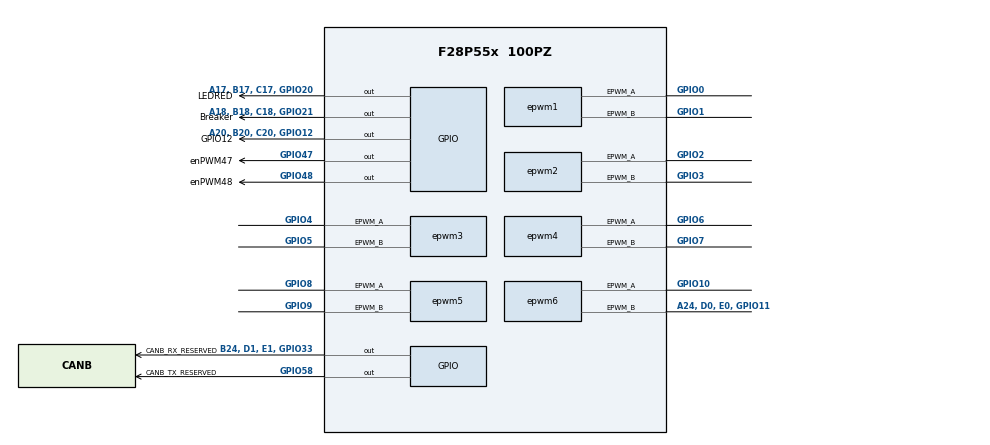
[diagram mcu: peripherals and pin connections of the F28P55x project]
/**
 * @cliArgs --device "F28P55x" --part "F28P55x_100PZ" --package "100PZ" --context "system" --product "C2000WARE@26.01.00.00"
 * @versions {"tool":"1.27.1+4634"}
 */

/**
 * Import the modules used in this configuration.
 */
const adc       = scripting.addModule("/driverlib/adc.js", {}, false);
const adc1      = adc.addInstance();
const adc2      = adc.addInstance();
const adc3      = adc.addInstance();
const adc4      = adc.addInstance();
const adc5      = adc.addInstance();
const analog    = scripting.addModule("/driverlib/analog.js", {}, false);
const analog1   = analog.addInstance();
const asysctl   = scripting.addModule("/driverlib/asysctl.js");
const cputimer  = scripting.addModule("/driverlib/cputimer.js", {}, false);
const cputimer1 = cputimer.addInstance();
const epwm      = scripting.addModule("/driverlib/epwm.js", {}, false);
const epwm1     = epwm.addInstance();
const epwm2     = epwm.addInstance();
const epwm3     = epwm.addInstance();
const epwm4     = epwm.addInstance();
const epwm5     = epwm.addInstance();
const epwm6     = epwm.addInstance();
const gpio      = scripting.addModule("/driverlib/gpio.js", {}, false);
const gpio1     = gpio.addInstance();
const gpio2     = gpio.addInstance();
const gpio3     = gpio.addInstance();
const gpio4     = gpio.addInstance();
const gpio5     = gpio.addInstance();
const gpio6     = gpio.addInstance();
const gpio7     = gpio.addInstance();

/**
 * Write custom configuration values to the imported modules.
 */
adc1.$name               = "ADC_A";
adc1.adcClockPrescaler   = "ADC_CLK_DIV_2_0";
adc1.soc0Trigger         = "ADC_TRIGGER_EPWM1_SOCA";
adc1.soc0SampleWindow    = 30;
adc1.soc1Trigger         = "ADC_TRIGGER_EPWM1_SOCA";
adc1.soc1SampleWindow    = 30;
adc1.soc2Trigger         = "ADC_TRIGGER_EPWM1_SOCA";
adc1.soc2SampleWindow    = 30;
adc1.soc3Channel         = "ADC_CH_ADCIN12";
adc1.soc3Trigger         = "ADC_TRIGGER_EPWM1_SOCA";
adc1.soc3SampleWindow    = 30;
adc1.enableTDMA          = false;
adc1.enabledInts         = ["ADC_INT_NUMBER1"];
adc1.enableInterrupt1    = true;
adc1.interruptPulseMode  = "ADC_PULSE_END_OF_CONV";
adc1.enabledSOCs         = ["ADC_SOC_NUMBER0","ADC_SOC_NUMBER1","ADC_SOC_NUMBER10","ADC_SOC_NUMBER11","ADC_SOC_NUMBER12","ADC_SOC_NUMBER13","ADC_SOC_NUMBER14","ADC_SOC_NUMBER15","ADC_SOC_NUMBER2","ADC_SOC_NUMBER3","ADC_SOC_NUMBER4","ADC_SOC_NUMBER5","ADC_SOC_NUMBER6","ADC_SOC_NUMBER7","ADC_SOC_NUMBER8","ADC_SOC_NUMBER9"];
adc1.soc4SampleWindow    = 30;
adc1.soc4Trigger         = "ADC_TRIGGER_EPWM1_SOCA";
adc1.soc5SampleWindow    = 30;
adc1.soc5Trigger         = "ADC_TRIGGER_EPWM1_SOCA";
adc1.soc6SampleWindow    = 30;
adc1.soc6Trigger         = "ADC_TRIGGER_EPWM1_SOCA";
adc1.soc7SampleWindow    = 30;
adc1.soc7Channel         = "ADC_CH_ADCIN12";
adc1.soc7Trigger         = "ADC_TRIGGER_EPWM1_SOCA";
adc1.soc8Trigger         = "ADC_TRIGGER_EPWM1_SOCA";
adc1.soc8SampleWindow    = 30;
adc1.soc9Trigger         = "ADC_TRIGGER_EPWM1_SOCA";
adc1.soc9SampleWindow    = 30;
adc1.soc10Trigger        = "ADC_TRIGGER_EPWM1_SOCA";
adc1.soc10SampleWindow   = 30;
adc1.soc11Channel        = "ADC_CH_ADCIN12";
adc1.soc11Trigger        = "ADC_TRIGGER_EPWM1_SOCA";
adc1.soc11SampleWindow   = 30;
adc1.soc12Trigger        = "ADC_TRIGGER_EPWM1_SOCA";
adc1.soc12SampleWindow   = 30;
adc1.soc13Trigger        = "ADC_TRIGGER_EPWM1_SOCA";
adc1.soc13SampleWindow   = 30;
adc1.soc14Trigger        = "ADC_TRIGGER_EPWM1_SOCA";
adc1.soc14SampleWindow   = 30;
adc1.soc15Channel        = "ADC_CH_ADCIN12";
adc1.soc15Trigger        = "ADC_TRIGGER_EPWM1_SOCA";
adc1.soc15SampleWindow   = 30;
adc1.interrupt1SOCSource = "ADC_INT_TRIGGER_EOC15";
adc1.soc1Channel         = "ADC_CH_ADCIN2";
adc1.soc2Channel         = "ADC_CH_ADCIN5";
adc1.soc5Channel         = "ADC_CH_ADCIN2";
adc1.soc6Channel         = "ADC_CH_ADCIN5";
adc1.soc9Channel         = "ADC_CH_ADCIN2";
adc1.soc10Channel        = "ADC_CH_ADCIN5";
adc1.soc13Channel        = "ADC_CH_ADCIN2";
adc1.soc14Channel        = "ADC_CH_ADCIN5";

adc2.$name               = "ADC_B";
adc2.adcBase             = "ADCB_BASE";
adc2.adcClockPrescaler   = "ADC_CLK_DIV_2_0";
adc2.soc0Trigger         = "ADC_TRIGGER_EPWM1_SOCA";
adc2.soc0SampleWindow    = 30;
adc2.enableTDMA          = false;
adc2.soc1Channel         = "ADC_CH_ADCIN1";
adc2.soc1Trigger         = "ADC_TRIGGER_EPWM1_SOCA";
adc2.soc1SampleWindow    = 30;
adc2.soc2Channel         = "ADC_CH_ADCIN8";
adc2.soc2Trigger         = "ADC_TRIGGER_EPWM1_SOCA";
adc2.soc2SampleWindow    = 30;
adc2.soc3SampleWindow    = 30;
adc2.soc3Channel         = "ADC_CH_ADCIN10";
adc2.soc3Trigger         = "ADC_TRIGGER_EPWM1_SOCA";
adc2.interruptPulseMode  = "ADC_PULSE_END_OF_CONV";
adc2.enabledInts         = ["ADC_INT_NUMBER1"];
adc2.enableInterrupt1    = true;
adc2.enabledSOCs         = ["ADC_SOC_NUMBER0","ADC_SOC_NUMBER1","ADC_SOC_NUMBER10","ADC_SOC_NUMBER11","ADC_SOC_NUMBER12","ADC_SOC_NUMBER13","ADC_SOC_NUMBER14","ADC_SOC_NUMBER15","ADC_SOC_NUMBER2","ADC_SOC_NUMBER3","ADC_SOC_NUMBER4","ADC_SOC_NUMBER5","ADC_SOC_NUMBER6","ADC_SOC_NUMBER7","ADC_SOC_NUMBER8","ADC_SOC_NUMBER9"];
adc2.soc4copyUse         = true;
adc2.soc4copyFrom        = "SOC0";
adc2.soc4Trigger         = "ADC_TRIGGER_EPWM1_SOCA";
adc2.soc4SampleWindow    = 30;
adc2.soc5copyUse         = true;
adc2.soc5copyFrom        = "SOC1";
adc2.soc5Channel         = "ADC_CH_ADCIN1";
adc2.soc5Trigger         = "ADC_TRIGGER_EPWM1_SOCA";
adc2.soc5SampleWindow    = 30;
adc2.soc6copyUse         = true;
adc2.soc6copyFrom        = "SOC2";
adc2.soc6Channel         = "ADC_CH_ADCIN8";
adc2.soc6Trigger         = "ADC_TRIGGER_EPWM1_SOCA";
adc2.soc6SampleWindow    = 30;
adc2.soc7copyUse         = true;
adc2.soc7copyFrom        = "SOC3";
adc2.soc7Channel         = "ADC_CH_ADCIN10";
adc2.soc7Trigger         = "ADC_TRIGGER_EPWM1_SOCA";
adc2.soc7SampleWindow    = 30;
adc2.soc8copyUse         = true;
adc2.soc8copyFrom        = "SOC0";
adc2.soc8Trigger         = "ADC_TRIGGER_EPWM1_SOCA";
adc2.soc8SampleWindow    = 30;
adc2.soc9copyUse         = true;
adc2.soc9copyFrom        = "SOC1";
adc2.soc9Channel         = "ADC_CH_ADCIN1";
adc2.soc9Trigger         = "ADC_TRIGGER_EPWM1_SOCA";
adc2.soc9SampleWindow    = 30;
adc2.soc10copyUse        = true;
adc2.soc10copyFrom       = "SOC2";
adc2.soc10Channel        = "ADC_CH_ADCIN8";
adc2.soc10Trigger        = "ADC_TRIGGER_EPWM1_SOCA";
adc2.soc10SampleWindow   = 30;
adc2.soc11copyUse        = true;
adc2.soc11copyFrom       = "SOC3";
adc2.soc11Channel        = "ADC_CH_ADCIN10";
adc2.soc11Trigger        = "ADC_TRIGGER_EPWM1_SOCA";
adc2.soc11SampleWindow   = 30;
adc2.soc12copyUse        = true;
adc2.soc12copyFrom       = "SOC0";
adc2.soc12Trigger        = "ADC_TRIGGER_EPWM1_SOCA";
adc2.soc12SampleWindow   = 30;
adc2.soc13copyUse        = true;
adc2.soc13copyFrom       = "SOC1";
adc2.soc13Channel        = "ADC_CH_ADCIN1";
adc2.soc13Trigger        = "ADC_TRIGGER_EPWM1_SOCA";
adc2.soc13SampleWindow   = 30;
adc2.soc14copyUse        = true;
adc2.soc14copyFrom       = "SOC2";
adc2.soc14Channel        = "ADC_CH_ADCIN8";
adc2.soc14Trigger        = "ADC_TRIGGER_EPWM1_SOCA";
adc2.soc14SampleWindow   = 30;
adc2.soc15copyUse        = true;
adc2.soc15copyFrom       = "SOC3";
adc2.soc15Channel        = "ADC_CH_ADCIN10";
adc2.soc15Trigger        = "ADC_TRIGGER_EPWM1_SOCA";
adc2.soc15SampleWindow   = 30;
adc2.interrupt1SOCSource = "ADC_INT_TRIGGER_EOC15";

adc3.$name               = "ADC_C";
adc3.adcBase             = "ADCC_BASE";
adc3.adcClockPrescaler   = "ADC_CLK_DIV_2_0";
adc3.enableTDMA          = false;
adc3.soc0Channel         = "ADC_CH_ADCIN4";
adc3.soc0Trigger         = "ADC_TRIGGER_EPWM1_SOCA";
adc3.soc0SampleWindow    = 30;
adc3.soc1Channel         = "ADC_CH_ADCIN8";
adc3.soc1SampleWindow    = 30;
adc3.soc1Trigger         = "ADC_TRIGGER_EPWM1_SOCA";
adc3.soc2Channel         = "ADC_CH_ADCIN14";
adc3.soc2SampleWindow    = 30;
adc3.soc2Trigger         = "ADC_TRIGGER_EPWM1_SOCA";
adc3.interruptPulseMode  = "ADC_PULSE_END_OF_CONV";
adc3.enabledInts         = ["ADC_INT_NUMBER1"];
adc3.enableInterrupt1    = true;
adc3.enabledSOCs         = ["ADC_SOC_NUMBER0","ADC_SOC_NUMBER1","ADC_SOC_NUMBER10","ADC_SOC_NUMBER11","ADC_SOC_NUMBER2","ADC_SOC_NUMBER3","ADC_SOC_NUMBER4","ADC_SOC_NUMBER5","ADC_SOC_NUMBER6","ADC_SOC_NUMBER7","ADC_SOC_NUMBER8","ADC_SOC_NUMBER9"];
adc3.soc3copyUse         = true;
adc3.soc3copyFrom        = "SOC0";
adc3.soc3Channel         = "ADC_CH_ADCIN4";
adc3.soc3Trigger         = "ADC_TRIGGER_EPWM1_SOCA";
adc3.soc3SampleWindow    = 30;
adc3.soc4copyUse         = true;
adc3.soc4copyFrom        = "SOC1";
adc3.soc4Channel         = "ADC_CH_ADCIN8";
adc3.soc4Trigger         = "ADC_TRIGGER_EPWM1_SOCA";
adc3.soc4SampleWindow    = 30;
adc3.soc5copyUse         = true;
adc3.soc5copyFrom        = "SOC2";
adc3.soc5Channel         = "ADC_CH_ADCIN14";
adc3.soc5Trigger         = "ADC_TRIGGER_EPWM1_SOCA";
adc3.soc5SampleWindow    = 30;
adc3.soc6copyUse         = true;
adc3.soc6copyFrom        = "SOC0";
adc3.soc6Channel         = "ADC_CH_ADCIN4";
adc3.soc6Trigger         = "ADC_TRIGGER_EPWM1_SOCA";
adc3.soc6SampleWindow    = 30;
adc3.soc7copyUse         = true;
adc3.soc7copyFrom        = "SOC1";
adc3.soc7Channel         = "ADC_CH_ADCIN8";
adc3.soc7Trigger         = "ADC_TRIGGER_EPWM1_SOCA";
adc3.soc7SampleWindow    = 30;
adc3.soc8copyUse         = true;
adc3.soc8copyFrom        = "SOC2";
adc3.soc8Channel         = "ADC_CH_ADCIN14";
adc3.soc8Trigger         = "ADC_TRIGGER_EPWM1_SOCA";
adc3.soc8SampleWindow    = 30;
adc3.soc9copyUse         = true;
adc3.soc9copyFrom        = "SOC0";
adc3.soc9Channel         = "ADC_CH_ADCIN4";
adc3.soc9Trigger         = "ADC_TRIGGER_EPWM1_SOCA";
adc3.soc9SampleWindow    = 30;
adc3.soc10copyUse        = true;
adc3.soc10copyFrom       = "SOC1";
adc3.soc10Channel        = "ADC_CH_ADCIN8";
adc3.soc10Trigger        = "ADC_TRIGGER_EPWM1_SOCA";
adc3.soc10SampleWindow   = 30;
adc3.soc11copyUse        = true;
adc3.soc11copyFrom       = "SOC2";
adc3.soc11Channel        = "ADC_CH_ADCIN14";
adc3.soc11Trigger        = "ADC_TRIGGER_EPWM1_SOCA";
adc3.soc11SampleWindow   = 30;
adc3.interrupt1SOCSource = "ADC_INT_TRIGGER_EOC11";

adc4.$name               = "ADC_D";
adc4.adcBase             = "ADCD_BASE";
adc4.adcClockPrescaler   = "ADC_CLK_DIV_2_0";
adc4.enableTDMA          = false;
adc4.soc0Channel         = "ADC_CH_ADCIN11";
adc4.soc0Trigger         = "ADC_TRIGGER_EPWM1_SOCA";
adc4.soc0SampleWindow    = 30;
adc4.soc1Channel         = "ADC_CH_ADCIN12";
adc4.soc1Trigger         = "ADC_TRIGGER_EPWM1_SOCA";
adc4.soc1SampleWindow    = 30;
adc4.soc2SampleWindow    = 30;
adc4.soc2Trigger         = "ADC_TRIGGER_EPWM1_SOCA";
adc4.interruptPulseMode  = "ADC_PULSE_END_OF_CONV";
adc4.enabledInts         = ["ADC_INT_NUMBER1"];
adc4.enableInterrupt1    = true;
adc4.soc3copyUse         = true;
adc4.soc3copyFrom        = "SOC0";
adc4.soc3Trigger         = "ADC_TRIGGER_EPWM1_SOCA";
adc4.soc3SampleWindow    = 30;
adc4.enabledSOCs         = ["ADC_SOC_NUMBER0","ADC_SOC_NUMBER1","ADC_SOC_NUMBER10","ADC_SOC_NUMBER11","ADC_SOC_NUMBER2","ADC_SOC_NUMBER3","ADC_SOC_NUMBER4","ADC_SOC_NUMBER5","ADC_SOC_NUMBER6","ADC_SOC_NUMBER7","ADC_SOC_NUMBER8","ADC_SOC_NUMBER9"];
adc4.soc4copyFrom        = "SOC2";
adc4.soc4copyUse         = true;
adc4.soc4SampleWindow    = 30;
adc4.soc4Trigger         = "ADC_TRIGGER_EPWM1_SOCA";
adc4.soc5SampleWindow    = 30;
adc4.soc5Trigger         = "ADC_TRIGGER_EPWM1_SOCA";
adc4.soc6Channel         = "ADC_CH_ADCIN11";
adc4.soc6copyUse         = true;
adc4.soc6SampleWindow    = 30;
adc4.soc6Trigger         = "ADC_TRIGGER_EPWM1_SOCA";
adc4.soc7Channel         = "ADC_CH_ADCIN12";
adc4.soc7Trigger         = "ADC_TRIGGER_EPWM1_SOCA";
adc4.soc7SampleWindow    = 30;
adc4.soc8Trigger         = "ADC_TRIGGER_EPWM1_SOCA";
adc4.soc8SampleWindow    = 30;
adc4.soc9Trigger         = "ADC_TRIGGER_EPWM1_SOCA";
adc4.soc9SampleWindow    = 30;
adc4.soc10Trigger        = "ADC_TRIGGER_EPWM1_SOCA";
adc4.soc10SampleWindow   = 30;
adc4.soc11Trigger        = "ADC_TRIGGER_EPWM1_SOCA";
adc4.soc11SampleWindow   = 30;
adc4.interrupt1SOCSource = "ADC_INT_TRIGGER_EOC11";
adc4.soc2Channel         = "ADC_CH_ADCIN11";
adc4.soc3Channel         = "ADC_CH_ADCIN12";
adc4.soc4Channel         = "ADC_CH_ADCIN11";
adc4.soc5Channel         = "ADC_CH_ADCIN12";
adc4.soc8Channel         = "ADC_CH_ADCIN11";
adc4.soc9Channel         = "ADC_CH_ADCIN12";
adc4.soc10Channel        = "ADC_CH_ADCIN11";
adc4.soc11Channel        = "ADC_CH_ADCIN12";

adc5.$name               = "ADC_E";
adc5.adcBase             = "ADCE_BASE";
adc5.adcClockPrescaler   = "ADC_CLK_DIV_2_0";
adc5.soc0Channel         = "ADC_CH_ADCIN12";
adc5.soc0Trigger         = "ADC_TRIGGER_EPWM1_SOCA";
adc5.soc0SampleWindow    = 30;
adc5.soc1Channel         = "ADC_CH_ADCIN15";
adc5.soc1Trigger         = "ADC_TRIGGER_EPWM1_SOCA";
adc5.soc1SampleWindow    = 30;
adc5.enabledInts         = ["ADC_INT_NUMBER1"];
adc5.interruptPulseMode  = "ADC_PULSE_END_OF_CONV";
adc5.enableInterrupt1    = true;
adc5.enabledSOCs         = ["ADC_SOC_NUMBER0","ADC_SOC_NUMBER1","ADC_SOC_NUMBER2","ADC_SOC_NUMBER3","ADC_SOC_NUMBER4","ADC_SOC_NUMBER5","ADC_SOC_NUMBER6","ADC_SOC_NUMBER7"];
adc5.soc2Channel         = "ADC_CH_ADCIN12";
adc5.soc2Trigger         = "ADC_TRIGGER_EPWM1_SOCA";
adc5.soc2SampleWindow    = 30;
adc5.soc3Channel         = "ADC_CH_ADCIN15";
adc5.soc3Trigger         = "ADC_TRIGGER_EPWM1_SOCA";
adc5.soc3SampleWindow    = 30;
adc5.soc4Channel         = "ADC_CH_ADCIN12";
adc5.soc4Trigger         = "ADC_TRIGGER_EPWM1_SOCA";
adc5.soc4SampleWindow    = 30;
adc5.soc5Channel         = "ADC_CH_ADCIN15";
adc5.soc5Trigger         = "ADC_TRIGGER_EPWM1_SOCA";
adc5.soc5SampleWindow    = 30;
adc5.soc6Channel         = "ADC_CH_ADCIN12";
adc5.soc6Trigger         = "ADC_TRIGGER_EPWM1_SOCA";
adc5.soc6SampleWindow    = 30;
adc5.soc7Channel         = "ADC_CH_ADCIN15";
adc5.soc7Trigger         = "ADC_TRIGGER_EPWM1_SOCA";
adc5.soc7SampleWindow    = 30;
adc5.interrupt1SOCSource = "ADC_INT_TRIGGER_EOC7";

analog1.$name            = "myANALOGPinMux0";
adc1.analog              = analog1;
analog1.useCase          = "CUSTOM";
adc2.analog              = analog1;
adc3.analog              = analog1;
adc4.analog              = analog1;
adc5.analog              = analog1;
analog1.useInterfacePins = ["A0, B15, C15, DACA_OUT","A1, B7, D11, CMP1_DACL","A10, B1, C10, GPIO230","A11, B10, C0, PGA2_OUT","A12, C5","A14, B14, C4, PGA1_OUT","A2, B6, C9, PGA1_INP, GPIO224","A4, B8","A5","A7, B30, C3, D12, E30","B0, C11, GPIO253","B2, C6, E12, GPIO226","B4, C8, GPIO236","B5, D15, E15, PGA3_OUT","C14, GPIO247"];

asysctl.analogReference        = "INTERNAL";
asysctl.analogReferenceVoltage = "1P65";

cputimer1.cputimerBase    = "CPUTIMER1_BASE";
cputimer1.timerPeriod     = 29999999;
cputimer1.$name           = "TIMER1";
cputimer1.emulationMode   = "CPUTIMER_EMULATIONMODE_RUNFREE";
cputimer1.enableInterrupt = true;
cputimer1.startTimer      = true;

epwm1.$name                                                      = "PWM1";
epwm1.epwmTimebase_counterMode                                   = "EPWM_COUNTER_MODE_UP_DOWN";
epwm1.epwmTimebase_hsClockDiv                                    = "EPWM_HSCLOCK_DIVIDER_1";
epwm1.epwmTimebase_period                                        = 7500;
epwm1.epwmTimebase_emulationMode                                 = "EPWM_EMULATION_FREE_RUN";
epwm1.epwmCounterCompare_cmpA                                    = 3750;
epwm1.epwmCounterCompare_cmpB                                    = 3750;
epwm1.epwmActionQualifier_EPWM_AQ_OUTPUT_A_ON_TIMEBASE_UP_CMPA   = "EPWM_AQ_OUTPUT_LOW";
epwm1.epwmActionQualifier_EPWM_AQ_OUTPUT_A_ON_TIMEBASE_DOWN_CMPA = "EPWM_AQ_OUTPUT_HIGH";
epwm1.epwmActionQualifier_EPWM_AQ_OUTPUT_B_ON_TIMEBASE_UP_CMPB   = "EPWM_AQ_OUTPUT_HIGH";
epwm1.epwmActionQualifier_EPWM_AQ_OUTPUT_B_ON_TIMEBASE_DOWN_CMPB = "EPWM_AQ_OUTPUT_LOW";
epwm1.epwmDeadband_polarityFED                                   = "EPWM_DB_POLARITY_ACTIVE_LOW";
epwm1.epwmDeadband_enableRED                                     = true;
epwm1.epwmDeadband_enableFED                                     = true;
epwm1.epwmDeadband_delayRED                                      = 60;
epwm1.epwmDeadband_delayFED                                      = 60;
epwm1.epwmTimebase_syncOutPulseMode                              = ["EPWM_SYNC_OUT_PULSE_ON_CNTR_ZERO"];
epwm1.epwmEventTrigger_EPWM_SOC_A_triggerEnable                  = true;
epwm1.epwmEventTrigger_EPWM_SOC_A_triggerSource                  = "EPWM_SOC_TBCTR_ZERO";
epwm1.epwmEventTrigger_EPWM_SOC_A_triggerEventPrescalar          = "1";
epwm1.epwmTripZone_EPWM_TZ_ACTION_EVENT_TZA                      = "EPWM_TZ_ACTION_LOW";
epwm1.epwmTripZone_EPWM_TZ_ACTION_EVENT_TZB                      = "EPWM_TZ_ACTION_LOW";
epwm1.epwmEventTrigger_enableInterrupt                           = true;
epwm1.epwmEventTrigger_interruptSource                           = "EPWM_INT_TBCTR_PERIOD";
epwm1.epwmEventTrigger_interruptEventCount                       = "1";
epwm1.epwm.$assign                                               = "EPWM1";
epwm1.epwm.epwm_aPin.$assign                                     = "GPIO0";
epwm1.epwm.epwm_bPin.$assign                                     = "GPIO1";

epwm2.$name                                                      = "PWM2";
epwm2.copyFrom                                                   = "PWM1";
epwm2.epwmTimebase_emulationMode                                 = "EPWM_EMULATION_FREE_RUN";
epwm2.epwmTimebase_hsClockDiv                                    = "EPWM_HSCLOCK_DIVIDER_1";
epwm2.epwmTimebase_period                                        = 7500;
epwm2.epwmTimebase_counterMode                                   = "EPWM_COUNTER_MODE_UP_DOWN";
epwm2.epwmCounterCompare_cmpA                                    = 3750;
epwm2.epwmCounterCompare_cmpB                                    = 3750;
epwm2.epwmActionQualifier_EPWM_AQ_OUTPUT_A_ON_TIMEBASE_UP_CMPA   = "EPWM_AQ_OUTPUT_LOW";
epwm2.epwmActionQualifier_EPWM_AQ_OUTPUT_A_ON_TIMEBASE_DOWN_CMPA = "EPWM_AQ_OUTPUT_HIGH";
epwm2.epwmActionQualifier_EPWM_AQ_OUTPUT_B_ON_TIMEBASE_UP_CMPB   = "EPWM_AQ_OUTPUT_HIGH";
epwm2.epwmActionQualifier_EPWM_AQ_OUTPUT_B_ON_TIMEBASE_DOWN_CMPB = "EPWM_AQ_OUTPUT_LOW";
epwm2.epwmDeadband_polarityFED                                   = "EPWM_DB_POLARITY_ACTIVE_LOW";
epwm2.epwmDeadband_enableRED                                     = true;
epwm2.epwmDeadband_delayRED                                      = 60;
epwm2.epwmDeadband_enableFED                                     = true;
epwm2.epwmDeadband_delayFED                                      = 60;
epwm2.epwmTimebase_phaseEnable                                   = true;
epwm2.epwmTimebase_counterModeAfterSync                          = "EPWM_COUNT_MODE_UP_AFTER_SYNC";
epwm2.copyUse                                                    = true;
epwm2.epwmTripZone_EPWM_TZ_ACTION_EVENT_TZA                      = "EPWM_TZ_ACTION_LOW";
epwm2.epwmTripZone_EPWM_TZ_ACTION_EVENT_TZB                      = "EPWM_TZ_ACTION_LOW";
epwm2.epwm.$assign                                               = "EPWM2";
epwm2.epwm.epwm_aPin.$assign                                     = "GPIO2";
epwm2.epwm.epwm_bPin.$assign                                     = "GPIO3";

epwm3.$name                                                      = "PWM3";
epwm3.epwmTimebase_emulationMode                                 = "EPWM_EMULATION_FREE_RUN";
epwm3.epwmTimebase_hsClockDiv                                    = "EPWM_HSCLOCK_DIVIDER_1";
epwm3.epwmTimebase_period                                        = 7500;
epwm3.epwmTimebase_counterMode                                   = "EPWM_COUNTER_MODE_UP_DOWN";
epwm3.epwmCounterCompare_cmpA                                    = 3750;
epwm3.epwmCounterCompare_cmpB                                    = 3750;
epwm3.epwmActionQualifier_EPWM_AQ_OUTPUT_A_ON_TIMEBASE_UP_CMPA   = "EPWM_AQ_OUTPUT_LOW";
epwm3.epwmActionQualifier_EPWM_AQ_OUTPUT_A_ON_TIMEBASE_DOWN_CMPA = "EPWM_AQ_OUTPUT_HIGH";
epwm3.epwmActionQualifier_EPWM_AQ_OUTPUT_B_ON_TIMEBASE_UP_CMPB   = "EPWM_AQ_OUTPUT_HIGH";
epwm3.epwmActionQualifier_EPWM_AQ_OUTPUT_B_ON_TIMEBASE_DOWN_CMPB = "EPWM_AQ_OUTPUT_LOW";
epwm3.epwmDeadband_polarityFED                                   = "EPWM_DB_POLARITY_ACTIVE_LOW";
epwm3.epwmDeadband_enableRED                                     = true;
epwm3.epwmDeadband_delayRED                                      = 60;
epwm3.epwmDeadband_enableFED                                     = true;
epwm3.epwmDeadband_delayFED                                      = 60;
epwm3.copyFrom                                                   = "PWM2";
epwm3.epwmTimebase_counterModeAfterSync                          = "EPWM_COUNT_MODE_UP_AFTER_SYNC";
epwm3.epwmTimebase_phaseEnable                                   = true;
epwm3.copyUse                                                    = true;
epwm3.epwmTripZone_EPWM_TZ_ACTION_EVENT_TZA                      = "EPWM_TZ_ACTION_LOW";
epwm3.epwmTripZone_EPWM_TZ_ACTION_EVENT_TZB                      = "EPWM_TZ_ACTION_LOW";
epwm3.epwm.$assign                                               = "EPWM3";
epwm3.epwm.epwm_aPin.$assign                                     = "GPIO4";
epwm3.epwm.epwm_bPin.$assign                                     = "GPIO5";

epwm4.$name                                                      = "PWM4";
epwm4.copyUse                                                    = true;
epwm4.copyFrom                                                   = "PWM2";
epwm4.epwmTimebase_emulationMode                                 = "EPWM_EMULATION_FREE_RUN";
epwm4.epwmTimebase_hsClockDiv                                    = "EPWM_HSCLOCK_DIVIDER_1";
epwm4.epwmTimebase_period                                        = 7500;
epwm4.epwmTimebase_counterMode                                   = "EPWM_COUNTER_MODE_UP_DOWN";
epwm4.epwmTimebase_counterModeAfterSync                          = "EPWM_COUNT_MODE_UP_AFTER_SYNC";
epwm4.epwmCounterCompare_cmpA                                    = 3750;
epwm4.epwmCounterCompare_cmpB                                    = 3750;
epwm4.epwmActionQualifier_EPWM_AQ_OUTPUT_A_ON_TIMEBASE_UP_CMPA   = "EPWM_AQ_OUTPUT_LOW";
epwm4.epwmActionQualifier_EPWM_AQ_OUTPUT_A_ON_TIMEBASE_DOWN_CMPA = "EPWM_AQ_OUTPUT_HIGH";
epwm4.epwmActionQualifier_EPWM_AQ_OUTPUT_B_ON_TIMEBASE_UP_CMPB   = "EPWM_AQ_OUTPUT_HIGH";
epwm4.epwmActionQualifier_EPWM_AQ_OUTPUT_B_ON_TIMEBASE_DOWN_CMPB = "EPWM_AQ_OUTPUT_LOW";
epwm4.epwmDeadband_polarityFED                                   = "EPWM_DB_POLARITY_ACTIVE_LOW";
epwm4.epwmDeadband_enableRED                                     = true;
epwm4.epwmDeadband_delayRED                                      = 60;
epwm4.epwmDeadband_enableFED                                     = true;
epwm4.epwmDeadband_delayFED                                      = 60;
epwm4.epwmTimebase_phaseEnable                                   = true;
epwm4.epwmTripZone_EPWM_TZ_ACTION_EVENT_TZA                      = "EPWM_TZ_ACTION_LOW";
epwm4.epwmTripZone_EPWM_TZ_ACTION_EVENT_TZB                      = "EPWM_TZ_ACTION_LOW";
epwm4.epwm.$assign                                               = "EPWM4";
epwm4.epwm.epwm_aPin.$assign                                     = "GPIO6";
epwm4.epwm.epwm_bPin.$assign                                     = "GPIO7";

epwm5.$name                                                      = "PWM5";
epwm5.copyUse                                                    = true;
epwm5.copyFrom                                                   = "PWM2";
epwm5.epwmTimebase_emulationMode                                 = "EPWM_EMULATION_FREE_RUN";
epwm5.epwmTimebase_hsClockDiv                                    = "EPWM_HSCLOCK_DIVIDER_1";
epwm5.epwmTimebase_period                                        = 7500;
epwm5.epwmTimebase_counterMode                                   = "EPWM_COUNTER_MODE_UP_DOWN";
epwm5.epwmTimebase_counterModeAfterSync                          = "EPWM_COUNT_MODE_UP_AFTER_SYNC";
epwm5.epwmCounterCompare_cmpA                                    = 3750;
epwm5.epwmCounterCompare_cmpB                                    = 3750;
epwm5.epwmActionQualifier_EPWM_AQ_OUTPUT_A_ON_TIMEBASE_UP_CMPA   = "EPWM_AQ_OUTPUT_LOW";
epwm5.epwmActionQualifier_EPWM_AQ_OUTPUT_A_ON_TIMEBASE_DOWN_CMPA = "EPWM_AQ_OUTPUT_HIGH";
epwm5.epwmActionQualifier_EPWM_AQ_OUTPUT_B_ON_TIMEBASE_UP_CMPB   = "EPWM_AQ_OUTPUT_HIGH";
epwm5.epwmActionQualifier_EPWM_AQ_OUTPUT_B_ON_TIMEBASE_DOWN_CMPB = "EPWM_AQ_OUTPUT_LOW";
epwm5.epwmDeadband_polarityFED                                   = "EPWM_DB_POLARITY_ACTIVE_LOW";
epwm5.epwmDeadband_enableRED                                     = true;
epwm5.epwmDeadband_delayRED                                      = 60;
epwm5.epwmDeadband_enableFED                                     = true;
epwm5.epwmDeadband_delayFED                                      = 60;
epwm5.epwmTimebase_phaseEnable                                   = true;
epwm5.epwmTripZone_EPWM_TZ_ACTION_EVENT_TZA                      = "EPWM_TZ_ACTION_LOW";
epwm5.epwmTripZone_EPWM_TZ_ACTION_EVENT_TZB                      = "EPWM_TZ_ACTION_LOW";
epwm5.epwm.$assign                                               = "EPWM5";
epwm5.epwm.epwm_aPin.$assign                                     = "GPIO8";
epwm5.epwm.epwm_bPin.$assign                                     = "GPIO9";

epwm6.$name                                                      = "PWM6";
epwm6.copyUse                                                    = true;
epwm6.copyFrom                                                   = "PWM2";
epwm6.epwmTimebase_emulationMode                                 = "EPWM_EMULATION_FREE_RUN";
epwm6.epwmTimebase_hsClockDiv                                    = "EPWM_HSCLOCK_DIVIDER_1";
epwm6.epwmTimebase_period                                        = 7500;
epwm6.epwmTimebase_counterMode                                   = "EPWM_COUNTER_MODE_UP_DOWN";
epwm6.epwmTimebase_counterModeAfterSync                          = "EPWM_COUNT_MODE_UP_AFTER_SYNC";
epwm6.epwmCounterCompare_cmpA                                    = 3750;
epwm6.epwmCounterCompare_cmpB                                    = 3750;
epwm6.epwmActionQualifier_EPWM_AQ_OUTPUT_A_ON_TIMEBASE_UP_CMPA   = "EPWM_AQ_OUTPUT_LOW";
epwm6.epwmActionQualifier_EPWM_AQ_OUTPUT_A_ON_TIMEBASE_DOWN_CMPA = "EPWM_AQ_OUTPUT_HIGH";
epwm6.epwmActionQualifier_EPWM_AQ_OUTPUT_B_ON_TIMEBASE_UP_CMPB   = "EPWM_AQ_OUTPUT_HIGH";
epwm6.epwmActionQualifier_EPWM_AQ_OUTPUT_B_ON_TIMEBASE_DOWN_CMPB = "EPWM_AQ_OUTPUT_LOW";
epwm6.epwmDeadband_polarityFED                                   = "EPWM_DB_POLARITY_ACTIVE_LOW";
epwm6.epwmDeadband_enableRED                                     = true;
epwm6.epwmDeadband_delayRED                                      = 60;
epwm6.epwmDeadband_enableFED                                     = true;
epwm6.epwmDeadband_delayFED                                      = 60;
epwm6.epwmTimebase_phaseEnable                                   = true;
epwm6.epwmTripZone_EPWM_TZ_ACTION_EVENT_TZA                      = "EPWM_TZ_ACTION_LOW";
epwm6.epwmTripZone_EPWM_TZ_ACTION_EVENT_TZB                      = "EPWM_TZ_ACTION_LOW";
epwm6.epwm.$assign                                               = "EPWM6";
epwm6.epwm.epwm_aPin.$assign                                     = "GPIO10";
epwm6.epwm.epwm_bPin.$assign                                     = "A24, D0, E0, GPIO11";

gpio1.$name             = "LEDRED";
gpio1.direction         = "GPIO_DIR_MODE_OUT";
gpio1.writeInitialValue = true;
gpio1.initialValue      = 1;
gpio1.gpioPin.$assign   = "A17, B17, C17, GPIO20";

gpio2.$name             = "enPWM48";
gpio2.direction         = "GPIO_DIR_MODE_OUT";
gpio2.writeInitialValue = true;
gpio2.initialValue      = 1;
gpio2.gpioPin.$assign   = "GPIO48";

gpio3.$name             = "enPWM47";
gpio3.direction         = "GPIO_DIR_MODE_OUT";
gpio3.writeInitialValue = true;
gpio3.initialValue      = 1;
gpio3.gpioPin.$assign   = "GPIO47";

gpio4.$name             = "Breaker";
gpio4.direction         = "GPIO_DIR_MODE_OUT";
gpio4.writeInitialValue = true;
gpio4.gpioPin.$assign   = "A18, B18, C18, GPIO21";

gpio5.$name             = "CANB_TX_RESERVED";
gpio5.direction         = "GPIO_DIR_MODE_OUT";
gpio5.writeInitialValue = true;
gpio5.initialValue      = 1;
gpio5.gpioPin.$assign   = "GPIO58";

gpio6.$name           = "CANB_RX_RESERVED";
gpio6.gpioPin.$assign = "B24, D1, E1, GPIO33";

gpio7.$name             = "GPIO12";
gpio7.direction         = "GPIO_DIR_MODE_OUT";
gpio7.writeInitialValue = true;
gpio7.initialValue      = 0;
gpio7.gpioPin.$assign   = "A20, B20, C20, GPIO12";


/**
 * Pinmux solution for unlocked pins/peripherals. This ensures that minor changes to the automatic solver in a future
 * version of the tool will not impact the pinmux you originally saw.  These lines can be completely deleted in order to
 * re-solve from scratch.
 */
analog1.analog.$suggestSolution                                     = "ANALOG";
analog1.analog["a0, b15, c15, daca_outPin"].$suggestSolution        = "A0, B15, C15, DACA_OUT";
analog1.analog["a2, b6, c9, pga1_inp, gpio224Pin"].$suggestSolution = "A2, B6, C9, PGA1_INP, GPIO224";
analog1.analog["a4, b8Pin"].$suggestSolution                        = "A4, B8";
analog1.analog.a5Pin.$suggestSolution                               = "A5";
analog1.analog["a7, b30, c3, d12, e30Pin"].$suggestSolution         = "A7, B30, C3, D12, E30";
analog1.analog["a10, b1, c10, gpio230Pin"].$suggestSolution         = "A10, B1, C10, GPIO230";
analog1.analog["a11, b10, c0, pga2_outPin"].$suggestSolution        = "A11, B10, C0, PGA2_OUT";
analog1.analog["a12, c5Pin"].$suggestSolution                       = "A12, C5";
analog1.analog["a14, b14, c4, pga1_outPin"].$suggestSolution        = "A14, B14, C4, PGA1_OUT";
analog1.analog["b0, c11, gpio253Pin"].$suggestSolution              = "B0, C11, GPIO253";
analog1.analog["b2, c6, e12, gpio226Pin"].$suggestSolution          = "B2, C6, E12, GPIO226";
analog1.analog["b4, c8, gpio236Pin"].$suggestSolution               = "B4, C8, GPIO236";
analog1.analog["b5, d15, e15, pga3_outPin"].$suggestSolution        = "B5, D15, E15, PGA3_OUT";
analog1.analog["c14, gpio247Pin"].$suggestSolution                  = "C14, GPIO247";
analog1.analog["a1, b7, d11, cmp1_daclPin"].$suggestSolution        = "A1, B7, D11, CMP1_DACL";
